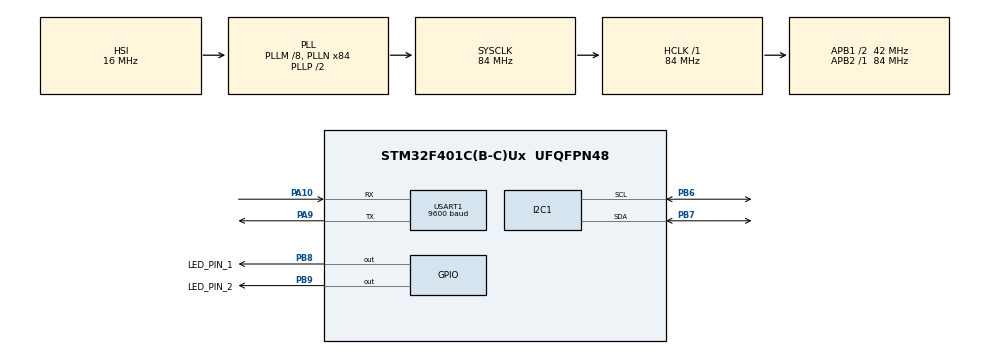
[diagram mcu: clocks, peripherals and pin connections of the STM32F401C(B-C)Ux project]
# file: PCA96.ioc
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Mcu.Family=STM32F4
Mcu.Name=STM32F401C(B-C)Ux
Mcu.Package=UFQFPN48
NVIC.PriorityGroup=NVIC_PRIORITYGROUP_4
PA10.Mode=Asynchronous
PA10.Signal=USART1_RX
PA9.Mode=Asynchronous
PA9.Signal=USART1_TX
PB6.Mode=I2C
PB6.Signal=I2C1_SCL
PB7.Mode=I2C
PB7.Signal=I2C1_SDA
PB8.GPIO_Label=LED_PIN_1
PB8.Signal=GPIO_Output
PB9.GPIO_Label=LED_PIN_2
PB9.PinState=GPIO_PIN_SET
PB9.Signal=GPIO_Output
ProjectManager.HeapSize=0x200
ProjectManager.StackSize=0x400
ProjectManager.TargetToolchain=STM32CubeIDE
RCC.48MHZClocksFreq_Value=42000000
RCC.AHBFreq_Value=84000000
RCC.APB1CLKDivider=RCC_HCLK_DIV2
RCC.APB1Freq_Value=42000000
RCC.APB1TimFreq_Value=84000000
RCC.APB2Freq_Value=84000000
RCC.APB2TimFreq_Value=84000000
RCC.CortexFreq_Value=84000000
RCC.HCLKFreq_Value=84000000
RCC.HSE_VALUE=25000000
RCC.HSI_VALUE=16000000
RCC.LSE_VALUE=32768
RCC.PLLM=8
RCC.PLLN=84
RCC.SYSCLKFreq_VALUE=84000000
RCC.SYSCLKSource=RCC_SYSCLKSOURCE_PLLCLK
RCC.VCOOutputFreq_Value=168000000
USART1.BaudRate=9600
USART1.VirtualMode=VM_ASYNC
board=custom

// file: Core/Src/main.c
/* USER CODE BEGIN Header */
/**
  ******************************************************************************
  * @file           : main.c
  * @brief          : Main program body
  ******************************************************************************
  * @attention
  *
  * Copyright (c) 2026 STMicroelectronics.
  * All rights reserved.
  *
  * This software is licensed under terms that can be found in the LICENSE file
  * in the root directory of this software component.
  * If no LICENSE file comes with this software, it is provided AS-IS.
  *
  ******************************************************************************
  */
/* USER CODE END Header */
#include "main.h"
#include "i2c.h"
#include "usart.h"
#include "gpio.h"

/* USER CODE BEGIN Includes */
#include "serial_print.h"
#include "pca9685.h"
/* USER CODE END Includes */

void SystemClock_Config(void);

int main(void)
{

  /* MCU Configuration--------------------------------------------------------*/

  /* Reset of all peripherals, Initializes the Flash interface and the Systick. */
  HAL_Init();

  /* Configure the system clock */
  SystemClock_Config();

  /* Initialize all configured peripherals */
  MX_GPIO_Init();
  MX_I2C1_Init();
  MX_USART1_UART_Init();
  /* USER CODE BEGIN 2 */
  PCA9685_Init(1000);

  /* USER CODE END 2 */

  /* Infinite loop */
  while (1)
  {
	PCA9685_SetFullOn(0);
	PCA9685_SetFullOff(1);
	PCA9685_SetFullOn(2);
	PCA9685_SetFullOff(3);
	PCA9685_SetFullOn(4);
	PCA9685_SetFullOff(5);
	PCA9685_SetFullOn(6);
	PCA9685_SetFullOff(7);
	PCA9685_SetFullOn(11);
	PCA9685_SetFullOff(12);
	PCA9685_SetFullOn(13);
	PCA9685_SetFullOff(14);
	PCA9685_SetFullOn(15);
  }
}

void SystemClock_Config(void)
{
  RCC_OscInitTypeDef RCC_OscInitStruct = {0};
  RCC_ClkInitTypeDef RCC_ClkInitStruct = {0};

  /** Configure the main internal regulator output voltage
  */
  __HAL_RCC_PWR_CLK_ENABLE();
  __HAL_PWR_VOLTAGESCALING_CONFIG(PWR_REGULATOR_VOLTAGE_SCALE2);

  /** Initializes the RCC Oscillators according to the specified parameters
  * in the RCC_OscInitTypeDef structure.
  */
  RCC_OscInitStruct.OscillatorType = RCC_OSCILLATORTYPE_HSI;
  RCC_OscInitStruct.HSIState = RCC_HSI_ON;
  RCC_OscInitStruct.HSICalibrationValue = RCC_HSICALIBRATION_DEFAULT;
  RCC_OscInitStruct.PLL.PLLState = RCC_PLL_ON;
  RCC_OscInitStruct.PLL.PLLSource = RCC_PLLSOURCE_HSI;
  RCC_OscInitStruct.PLL.PLLM = 8;
  RCC_OscInitStruct.PLL.PLLN = 84;
  RCC_OscInitStruct.PLL.PLLP = RCC_PLLP_DIV2;
  RCC_OscInitStruct.PLL.PLLQ = 4;
  if (HAL_RCC_OscConfig(&RCC_OscInitStruct) != HAL_OK)
  {
    Error_Handler();
  }
  /* FLASH_ACR configuration for 84MHz */
    __HAL_FLASH_SET_LATENCY(FLASH_LATENCY_2);

  /** Initializes the CPU, AHB and APB buses clocks
  */
  RCC_ClkInitStruct.ClockType = RCC_CLOCKTYPE_HCLK|RCC_CLOCKTYPE_SYSCLK
                              |RCC_CLOCKTYPE_PCLK1|RCC_CLOCKTYPE_PCLK2;
  RCC_ClkInitStruct.SYSCLKSource = RCC_SYSCLKSOURCE_PLLCLK;
  RCC_ClkInitStruct.AHBCLKDivider = RCC_SYSCLK_DIV1;
  RCC_ClkInitStruct.APB1CLKDivider = RCC_HCLK_DIV2;
  RCC_ClkInitStruct.APB2CLKDivider = RCC_HCLK_DIV1;

  if (HAL_RCC_ClockConfig(&RCC_ClkInitStruct, FLASH_LATENCY_2) != HAL_OK)
  {
    Error_Handler();
  }
}

void Error_Handler(void)
{
  __disable_irq();
  while (1)
  {
  }
}
